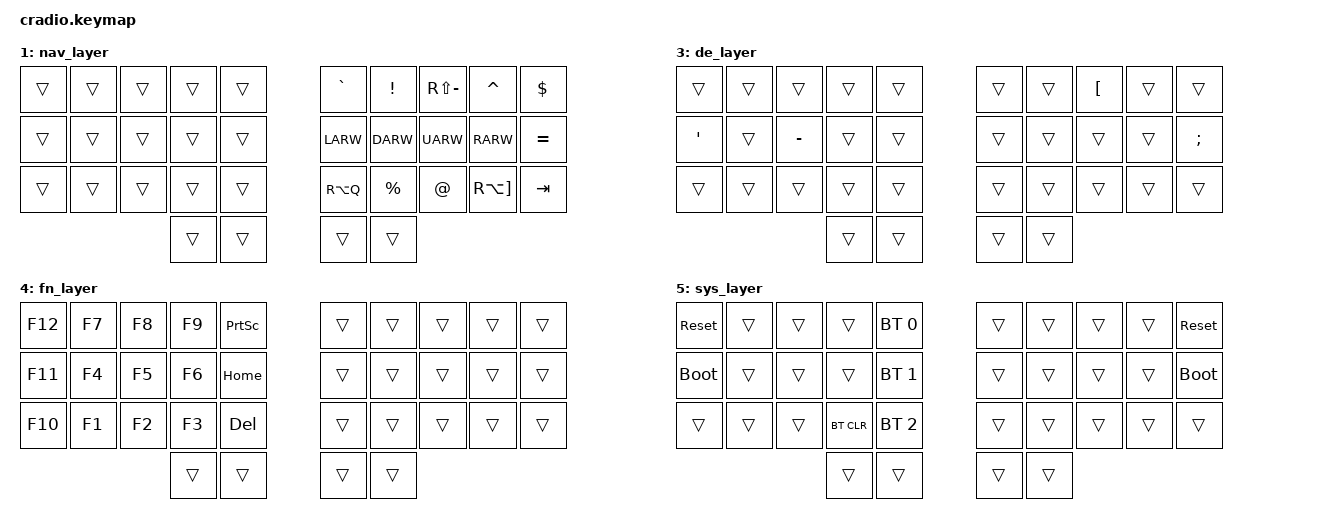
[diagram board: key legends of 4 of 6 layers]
// Copyright (c) 2022 The ZMK Contributors
// SPDX-License-Identifier: MIT

#include <behaviors.dtsi>
#include <dt-bindings/zmk/keys.h>
#include <dt-bindings/zmk/bt.h>

#define DEFAULT 0
#define NAV 1
#define NUMS 2
#define DE 3
#define FN 4
#define SYS 5

// Home row mods macro
#define HRML(k1,k2,k3,k4) &ht LCTRL k1  &ht LALT k2  &ht LGUI k3  &ht LSHFT k4
#define HRMR(k1,k2,k3,k4) &ht RSHFT k1  &ht RGUI k2  &ht RALT k3  &ht RCTRL k4

&lt {
    flavor = "tap-preferred";
    tapping-term-ms = <200>;
    quick-tap-ms = <200>;
};

&sk {
    release-after-ms = <1500>;
    /delete-property/ ignore-modifiers;
};

/ {
     behaviors {
        ht: hold_tap {
            compatible = "zmk,behavior-hold-tap";
            #binding-cells = <2>;
            flavor = "tap-preferred";
            tapping-term-ms = <200>;
            quick-tap-ms = <300>;
            require-prior-idle-ms = <200>;
            bindings = <&kp>, <&kp>;
        };
    };
    
    combos {
        compatible = "zmk,combos";
        combe_sys_left {
            timeout-ms = <50>;
            key-positions = <30 31>;
            bindings = <&mo SYS>;
        };
        combo_sys_right {
            timeout-ms = <50>;
            key-positions = <32 33>;
            bindings = <&mo SYS>;
        };

    };



    keymap {
        compatible = "zmk,keymap";
        default_layer {
            bindings = <
        //╭─0────────┬──────────┬──────────┬──────────┬──────────╮   ╭──────────┬──────────┬──────────┬──────────┬──────────╮
        //│  Q       │  W       │  F       │  P       │  B       │   │  J       │  L       │  U       │  Y       │ - _      │
            &kp Q      &kp W      &kp F      &kp P      &kp B          &kp J      &kp L      &kp U      &kp Y      &kp FSLH
        //├─10───────┼──11──────┼──12──────┼──3───────┼──4───────┤   ├────5─────┼──6───────┼──7───────┼─8────────┼─9────────┤
        //│  A       │  R       │  S       │  T       │  G       │   │  M       │  N       │  E       │  I       │ O        │
            &kp A      &kp R      &kp S      &kp T      &kp G          &kp M      &kp N      &kp E      &kp I      &kp O
        //├─20───────┼──────────┼──────────┼──────────┼──────────┤   ├──────────┼──────────┼──────────┼──────────┼──────────┤
        //│  Z       │  X       │  C       │  D       │  V       │   │  K       │  H       │ , <      │ . >      │ # '      │
            HRML(Z,    X,         C,         D)        &kp V          &kp K      HRMR(H,    COMMA,         DOT,      BSLH)
        //╰──────────┴──────────┴──────────┼───30─────┼──────────┤   ├──────────┼──────────┼──────────┴──────────┴──────────╯
                                            &lt NAV ESC  &sk LSHIFT   &kp SPACE &lt NUMS ENTER
        //                                 ╰──────────┴──────────╯   ╰──────────┴──────────╯
            >;
        };

        nav_layer {
            bindings = <
        //╭──────────┬──────────┬──────────┬──────────┬──────────╮   ╭──────────┬──────────┬──────────┬──────────┬──────────╮
        //│          │          │          │          │          │   │ ^        │ !        │ ?        │ &        │  $       │
            &trans     &trans     &trans     &trans     &trans        &kp GRAVE &kp EXCL &kp RS(MINUS) &kp CARET &kp DLLR
        //├──────────┼──────────┼──────────┼──────────┼──────────┤   ├──────────┼──────────┼──────────┼──────────┼──────────┤
        //│          │          │          │          │          │   │ LEFT     │ DOWN     │ UP       │ RIGHT    │  ;       │
            &trans     &trans     &trans     &trans     &trans         &kp LARW   &kp DARW   &kp UARW   &kp RARW   &kp EQUAL
        //├──────────┼──────────┼──────────┼──────────┼──────────┤   ├──────────┼──────────┼──────────┼──────────┼──────────┤
        //│          │          │          │          │          │   │ @        │ %        │ "        │ ~        │          │
        &trans     &trans     &trans     &trans     &trans         &kp RA(Q)  &kp PRCNT  &kp AT     &kp RA(RBKT)  &kp TAB
        //╰──────────┴──────────┴──────────┼──────────┼──────────┤   ├──────────┼──────────┼──────────┴──────────┴──────────╯
                                             &trans     &trans        &trans     &trans
        //                                 ╰──────────┴──────────╯   ╰──────────┴──────────╯
            >;
        };

        nums_layer {
            bindings = <
        //╭──────────┬──────────┬──────────┬──────────┬──────────╮   ╭──────────┬──────────┬──────────┬──────────┬──────────╮
        //│  *       │  7       │  8       │  9       │  +       │   │  /       │   <      │   >      │          │          │
           &kp RS(RBKT) &kp N7    &kp N8     &kp N9     &kp RBKT        &kp AMPS  &kp NUBS  &kp LS(NUBS) &sl FN     &sl DE 
        //├──────────┼──────────┼──────────┼──────────┼──────────┤   ├──────────┼──────────┼──────────┼──────────┼──────────┤
        //│  7       │  4       │  5       │  6       │  -       │   │  |       │  (       │  )       │  {       │  }       │  
            &kp AMPS   &kp N4     &kp N5     &kp N6     &kp FSLH       &kp RA(NUBS) &kp RS(N8) &kp RS(N9) &kp RA(N7) &kp RA(N0)  
        //├──────────┼──────────┼──────────┼──────────┼──────────┤   ├──────────┼──────────┼──────────┼──────────┼──────────┤
        //│  0       │  1       │  2       │  3       │  =       │   │  \       │  [       │  ]       │  <       │  >       │
            &kp N0     &kp N1     &kp N2     &kp N3     &kp RS(N0) &kp RA(MINUS) HRMR(RA(N8), RA(N9), NUBS,   RS(NUBS))
        //╰──────────┴──────────┴──────────┼──────────┼──────────┤   ├──────────┼──────────┼──────────┴──────────┴──────────╯
                                             &kp DEL    &kp BSPC         &trans     &trans
        //                                 ╰──────────┴──────────╯   ╰──────────┴──────────╯
            >;
        };

        de_layer {
            bindings = <
        //╭──────────┬──────────┬──────────┬──────────┬──────────╮   ╭──────────┬──────────┬──────────┬──────────┬──────────╮
        //│          │          │          │          │          │   │          │          │  ü       │          │          │
           &trans      &trans     &trans     &trans     &trans         &trans     &trans     &kp LBKT   &trans     &trans 
        //├──────────┼──────────┼──────────┼──────────┼──────────┤   ├──────────┼──────────┼──────────┼──────────┼──────────┤
        //│  ä       │          │  ß       │          │          │   │          │          │          │          │  ö       │
            &kp SQT    &trans     &kp MINUS  &trans     &trans         &trans     &trans     &trans     &trans     &kp SEMI  
        //├──────────┼──────────┼──────────┼──────────┼──────────┤   ├──────────┼──────────┼──────────┼──────────┼──────────┤
        //│          │          │          │          │          │   │          │          │          │          │          │
            &trans     &trans     &trans     &trans     &trans         &trans     &trans     &trans     &trans     &trans
        //╰──────────┴──────────┴──────────┼──────────┼──────────┤   ├──────────┼──────────┼──────────┴──────────┴──────────╯
                                             &trans     &trans         &trans     &trans
        //                                 ╰──────────┴──────────╯   ╰──────────┴──────────╯
            >;
        };

        fn_layer {
            bindings = <
        //╭──────────┬──────────┬──────────┬──────────┬──────────╮   ╭──────────┬──────────┬──────────┬──────────┬──────────╮
        //│          │          │          │          │          │   │          │          │          │          │          │
            &kp F12     &kp F7     &kp F8     &kp F9    &kp PSCRN       &trans     &trans     &trans     &trans    &trans
        //├──────────┼──────────┼──────────┼──────────┼──────────┤   ├──────────┼──────────┼──────────┼──────────┼──────────┤
        //│          │          │          │          │          │   │          │          │          │          │
            &kp F11     &kp F4     &kp F5     &kp F6    &kp HOME        &trans     &trans     &trans     &trans     &trans
        //├──────────┼──────────┼──────────┼──────────┼──────────┤   ├──────────┼──────────┼──────────┼──────────┼──────────┤
        //│          │          │          │          │          │   │          │          │          │          │          │
            &kp F10     &kp F1     &kp F2     &kp F3    &kp DEL         &trans     &trans     &trans     &trans     &trans
        //╰──────────┴──────────┴──────────┼──────────┼──────────┤   ├──────────┼──────────┼──────────┴──────────┴──────────╯
                                             &trans     &trans         &trans     &trans
        //                                 ╰──────────┴──────────╯   ╰──────────┴──────────╯
            >;
        };

        sys_layer {
            bindings = <
        //╭──────────┬──────────┬──────────┬──────────┬──────────╮   ╭──────────┬──────────┬──────────┬──────────┬──────────╮
        //│ RESET    │          │          │          │PROFILE 0 │   │          │          │          │          │  RESET   │
           &sys_reset  &trans     &trans     &trans    &bt BT_SEL 0    &trans     &trans     &trans     &trans    &sys_reset
        //├──────────┼──────────┼──────────┼──────────┼──────────┤   ├──────────┼──────────┼──────────┼──────────┼──────────┤
        //│BOOTLOADER│          │          │          │PROFILE 1 │   │          │          │          │          │BOOTLOADER│
          &bootloader  &trans     &trans     &trans    &bt BT_SEL 1    &trans     &trans     &trans     &trans    &bootloader
        //├──────────┼──────────┼──────────┼──────────┼──────────┤   ├──────────┼──────────┼──────────┼──────────┼──────────┤
        //│          │          │          │ CLEAR BT │PROFILE 2 │   │          │          │          │          │          │
            &trans     &trans     &trans    &bt BT_CLR &bt BT_SEL 2    &trans     &trans     &trans     &trans     &trans
        //╰──────────┴──────────┴──────────┼──────────┼──────────┤   ├──────────┼──────────┼──────────┴──────────┴──────────╯
                                             &trans     &trans         &trans     &trans
        //                                 ╰──────────┴──────────╯   ╰──────────┴──────────╯
            >;
        };
    };
};
